# STM32N655 register map
File version: 1.0
CPU: CM55 r0p1, little endian, no MPU, FPU, vendor SysTick, 8 interrupt priority bits
Registers are 32-bit, read-write, reset 0x0 unless marked. A register's access mark holds for its fields unless they carry their own. Offsets are from the block's base; [hi:lo] are bit positions; {n}, {i} and the like mark numbered series; 'fields as' and 'values as' point back to an identical list.

## RIFSC — Resource isolation framework security controller
Base 0x44024000
Same registers: RIFSC_S 0x54024000
0x00 RIFSC_RISC_CR — RIFSC RISC slave configuration register x
  [0] GLOCK — Global lock
    0=RIFSC RISC registers are writable; 1=All writes to RIFSC RISC registers are ignored
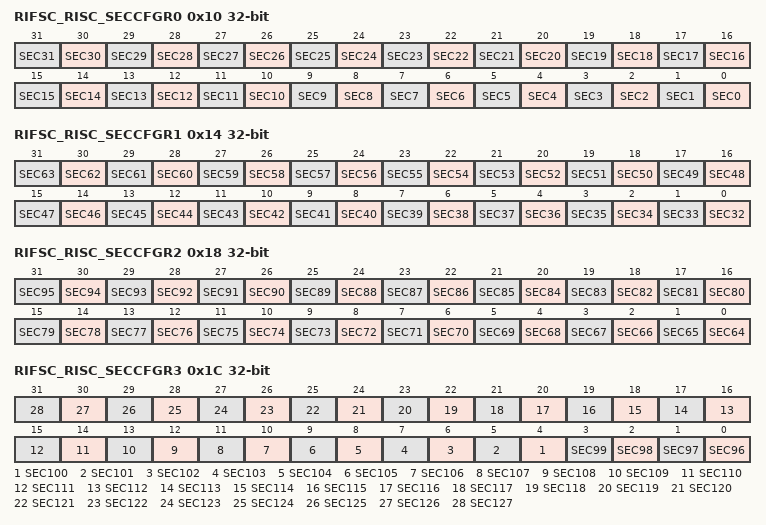
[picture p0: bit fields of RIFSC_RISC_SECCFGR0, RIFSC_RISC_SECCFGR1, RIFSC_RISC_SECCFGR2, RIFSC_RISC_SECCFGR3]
0x10 RIFSC_RISC_SECCFGR0 — RIFSC RISC slave security configuration register 0
  [n] SEC{n} (n=0..31) — security configuration for peripheral {n}
    0=Secure and non-secure data access are granted to the peripheral {n}; 1=Secure data access only are granted to the peripheral {n}
0x14 RIFSC_RISC_SECCFGR1 — RIFSC RISC slave security configuration register 1
  [n-32] SEC{n} (n=32..63) — security configuration for peripheral {n}
    values as RIFSC_RISC_SECCFGR0.SEC0
0x18 RIFSC_RISC_SECCFGR2 — RIFSC RISC slave security configuration register 2
  [n-64] SEC{n} (n=64..95) — security configuration for peripheral {n}
    values as RIFSC_RISC_SECCFGR0.SEC0
0x1C RIFSC_RISC_SECCFGR3 — RIFSC RISC slave security configuration register 3
  [n-96] SEC{n} (n=96..127) — security configuration for peripheral {n}
    values as RIFSC_RISC_SECCFGR0.SEC0
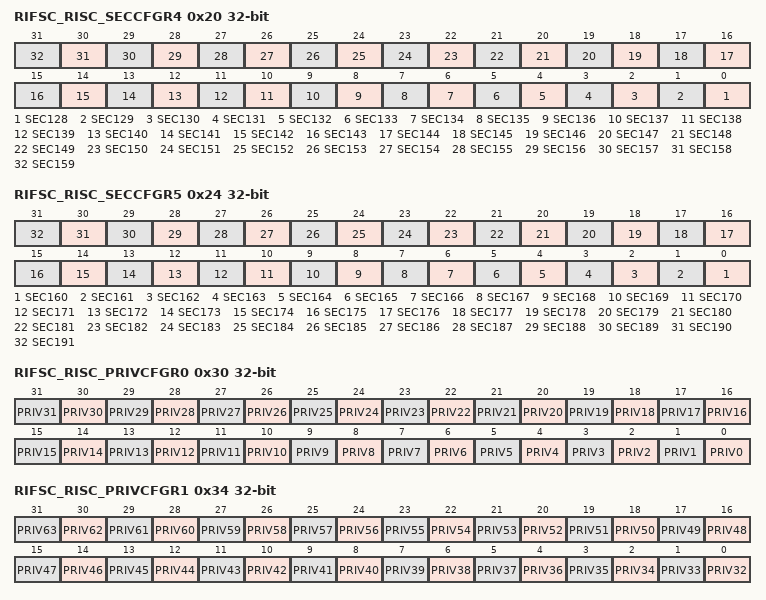
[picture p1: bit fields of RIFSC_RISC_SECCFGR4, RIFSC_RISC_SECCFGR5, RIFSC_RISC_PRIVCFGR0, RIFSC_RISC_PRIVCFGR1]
0x20 RIFSC_RISC_SECCFGR4 — RIFSC RISC slave security configuration register 4
  [n-128] SEC{n} (n=128..159) — security configuration for peripheral {n}
    values as RIFSC_RISC_SECCFGR0.SEC0
0x24 RIFSC_RISC_SECCFGR5 — RIFSC RISC slave security configuration register 5
  [n-160] SEC{n} (n=160..191) — security configuration for peripheral {n}
    values as RIFSC_RISC_SECCFGR0.SEC0
0x30 RIFSC_RISC_PRIVCFGR0 — RIFSC RISFC slave privileged register 0
  [n] PRIV{n} (n=0..31) — privileged-only access permission for peripheral {n}
    0=Privileged and unprivileged data access are granted to the peripheral {n}; 1=Privileged data access only are granted to the peripheral {n}
0x34 RIFSC_RISC_PRIVCFGR1 — RIFSC RISFC slave privileged register 1
  [n-32] PRIV{n} (n=32..63) — privileged-only access permission for peripheral {n}
    values as RIFSC_RISC_PRIVCFGR0.PRIV0
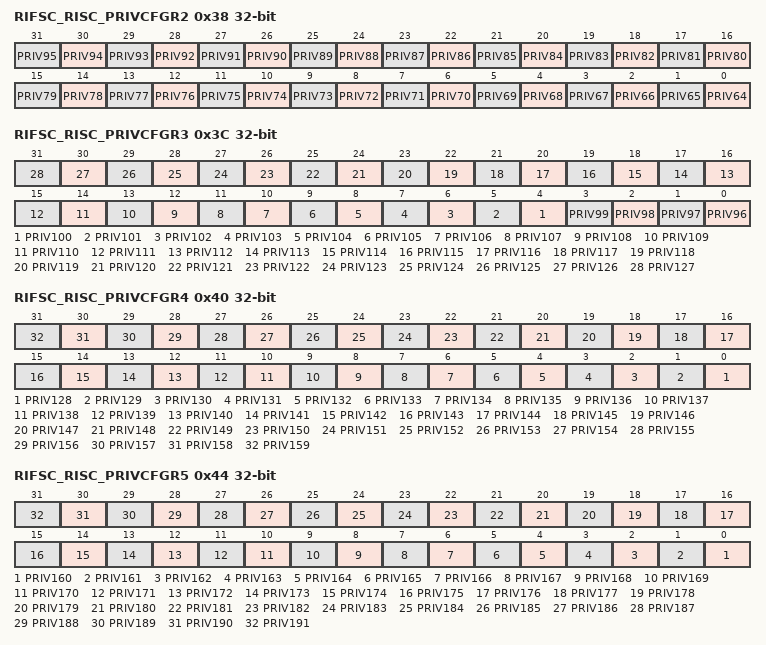
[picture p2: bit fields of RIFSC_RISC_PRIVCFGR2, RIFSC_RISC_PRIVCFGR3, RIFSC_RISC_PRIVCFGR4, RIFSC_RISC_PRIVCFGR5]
0x38 RIFSC_RISC_PRIVCFGR2 — RIFSC RISFC slave privileged register 2
  [n-64] PRIV{n} (n=64..95) — privileged-only access permission for peripheral {n}
    values as RIFSC_RISC_PRIVCFGR0.PRIV0
0x3C RIFSC_RISC_PRIVCFGR3 — RIFSC RISFC slave privileged register 3
  [n-96] PRIV{n} (n=96..127) — privileged-only access permission for peripheral {n}
    values as RIFSC_RISC_PRIVCFGR0.PRIV0
0x40 RIFSC_RISC_PRIVCFGR4 — RIFSC RISFC slave privileged register 4
  [n-128] PRIV{n} (n=128..159) — privileged-only access permission for peripheral {n}
    values as RIFSC_RISC_PRIVCFGR0.PRIV0
0x44 RIFSC_RISC_PRIVCFGR5 — RIFSC RISFC slave privileged register 5
  [n-160] PRIV{n} (n=160..191) — privileged-only access permission for peripheral {n}
    values as RIFSC_RISC_PRIVCFGR0.PRIV0
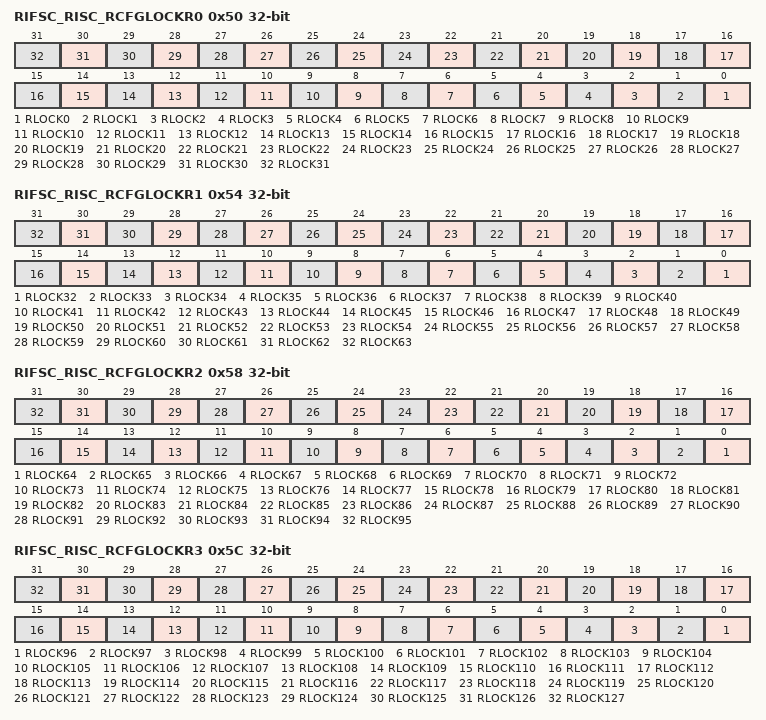
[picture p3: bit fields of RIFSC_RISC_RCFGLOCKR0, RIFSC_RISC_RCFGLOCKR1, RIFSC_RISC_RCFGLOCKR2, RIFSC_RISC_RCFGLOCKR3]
0x50 RIFSC_RISC_RCFGLOCKR0 — RIFSC RISC slave resource configuration lock register 0
  [n] RLOCK{n} (n=0..31) — resource lock for peripheral {n}
    0=SEC{n} in RIFSC_RISC_SECCFGRx and PRIV{n} in RIFSC_RISC_PRIVCFGRx are writable; 1=Writes to SEC{n} and PRIV{n} are ignored
0x54 RIFSC_RISC_RCFGLOCKR1 — RIFSC RISC slave resource configuration lock register 1
  [n-32] RLOCK{n} (n=32..63) — resource lock for peripheral {n}
    values as RIFSC_RISC_RCFGLOCKR0.RLOCK0
0x58 RIFSC_RISC_RCFGLOCKR2 — RIFSC RISC slave resource configuration lock register 2
  [n-64] RLOCK{n} (n=64..95) — resource lock for peripheral {n}
    values as RIFSC_RISC_RCFGLOCKR0.RLOCK0
0x5C RIFSC_RISC_RCFGLOCKR3 — RIFSC RISC slave resource configuration lock register 3
  [n-96] RLOCK{n} (n=96..127) — resource lock for peripheral {n}
    values as RIFSC_RISC_RCFGLOCKR0.RLOCK0
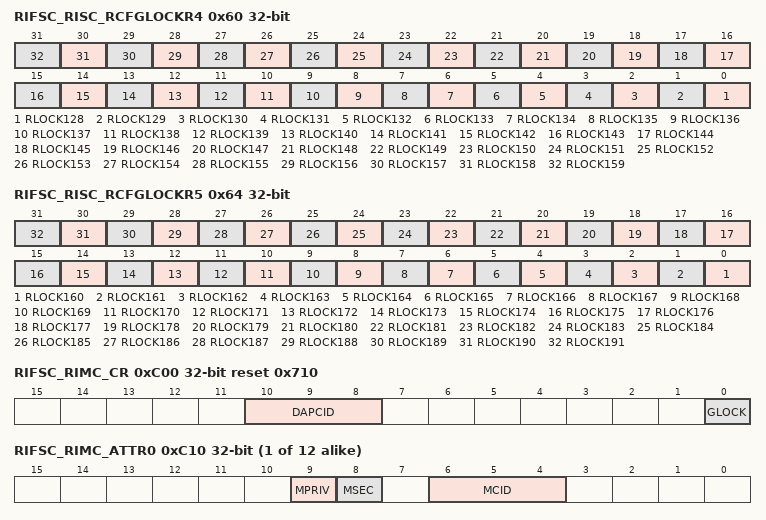
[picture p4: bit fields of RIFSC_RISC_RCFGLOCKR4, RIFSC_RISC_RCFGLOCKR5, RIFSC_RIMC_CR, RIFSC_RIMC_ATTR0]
0x60 RIFSC_RISC_RCFGLOCKR4 — RIFSC RISC slave resource configuration lock register 4
  [n-128] RLOCK{n} (n=128..159) — resource lock for peripheral {n}
    values as RIFSC_RISC_RCFGLOCKR0.RLOCK0
0x64 RIFSC_RISC_RCFGLOCKR5 — RIFSC RISC slave resource configuration lock register 5
  [n-160] RLOCK{n} (n=160..191) — resource lock for peripheral {n}
    values as RIFSC_RISC_RCFGLOCKR0.RLOCK0
0xC00 RIFSC_RIMC_CR reset 0x710 — RIFSC RIMC master configuration register
  [10:8] DAPCID — debug access port compartment ID
  [0] GLOCK — global lock
    0=RIFSC RIMC registers are writable; 1=All writes to RIFSC RIMC registers are ignored
{0xC10+4i} RIFSC_RIMC_ATTR{i} (i=0..11) — RIFSC RIMC master attribute register {i}
  [9] MPRIV — master privileged
    0=This master is unprivileged; 1=This master is privileged
  [8] MSEC — master secure
    0=This master is non-secure; 1=This master is secure
  [6:4] MCID — master CID
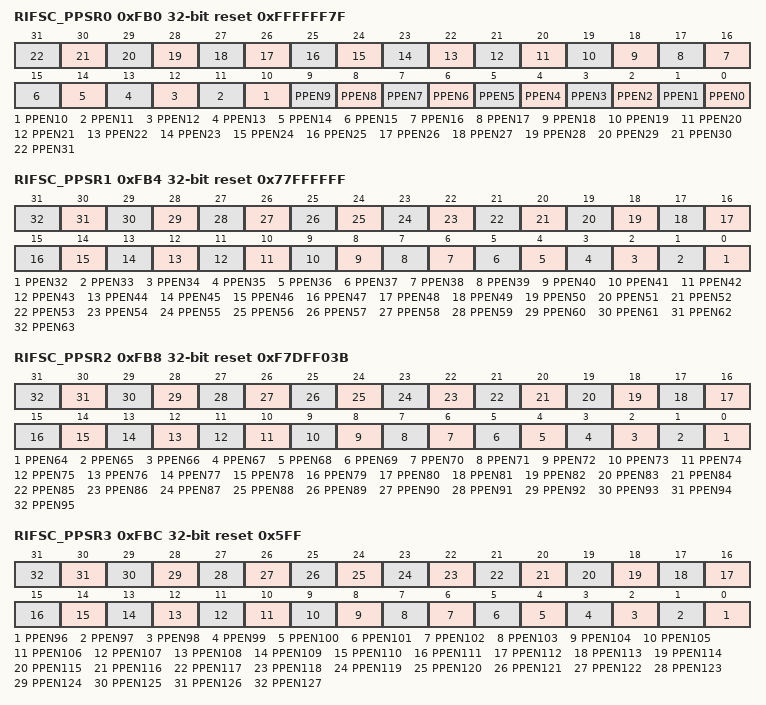
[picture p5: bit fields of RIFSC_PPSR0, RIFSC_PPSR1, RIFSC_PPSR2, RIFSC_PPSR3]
0xFB0 RIFSC_PPSR0 ro reset 0xFFFFFF7F — RIFSC peripheral protection status register 0
  [n] PPEN{n} (n=0..31) — peripheral protection enable {n}
    0=SEC{n}, PRIV{n}, and RLOCK{n} register bit not present; 1=SEC{n}, PRIV{n}, and RLOCK{n} register bit present
0xFB4 RIFSC_PPSR1 ro reset 0x77FFFFFF — RIFSC peripheral protection status register 1
  [n-32] PPEN{n} (n=32..63) — peripheral protection enable {n}
    values as RIFSC_PPSR0.PPEN0
0xFB8 RIFSC_PPSR2 ro reset 0xF7DFF03B — RIFSC peripheral protection status register 2
  [n-64] PPEN{n} (n=64..95) — peripheral protection enable {n}
    values as RIFSC_PPSR0.PPEN0
0xFBC RIFSC_PPSR3 ro reset 0x5FF — RIFSC peripheral protection status register 3
  [n-96] PPEN{n} (n=96..127) — peripheral protection enable {n}
    values as RIFSC_PPSR0.PPEN0
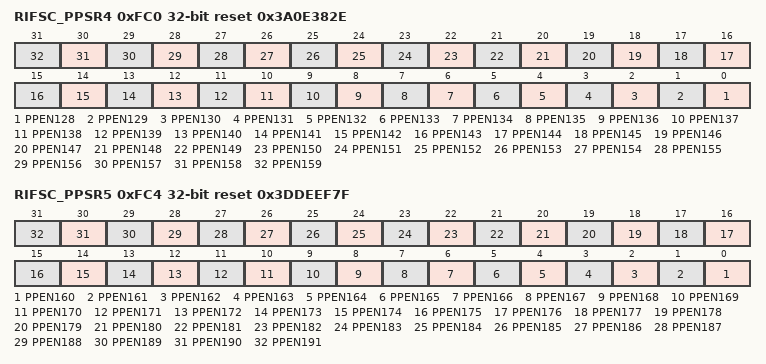
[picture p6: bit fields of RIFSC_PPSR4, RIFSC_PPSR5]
0xFC0 RIFSC_PPSR4 ro reset 0x3A0E382E — RIFSC peripheral protection status register 4
  [n-128] PPEN{n} (n=128..159) — peripheral protection enable {n}
    values as RIFSC_PPSR0.PPEN0
0xFC4 RIFSC_PPSR5 ro reset 0x3DDEEF7F — RIFSC peripheral protection status register 5
  [n-160] PPEN{n} (n=160..191) — peripheral protection enable {n}
    values as RIFSC_PPSR0.PPEN0
